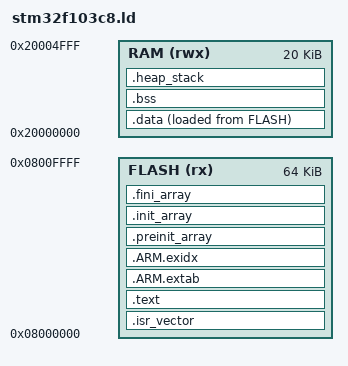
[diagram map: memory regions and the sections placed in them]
/* STM32F103C8: match the original Keil 64 KiB flash / 20 KiB RAM layout. */
ENTRY(Reset_Handler)

MEMORY
{
    FLASH (rx) : ORIGIN = 0x08000000, LENGTH = 64K
    RAM (rwx)  : ORIGIN = 0x20000000, LENGTH = 20K
}

_estack = ORIGIN(RAM) + LENGTH(RAM);
_Min_Heap_Size = 0x200;
_Min_Stack_Size = 0x400;

SECTIONS
{
    .isr_vector :
    {
        . = ALIGN(4);
        KEEP(*(.isr_vector))
    } > FLASH

    .text :
    {
        . = ALIGN(4);
        *(.text*)
        *(.rodata*)
        KEEP(*(.init))
        KEEP(*(.fini))
        . = ALIGN(4);
        _etext = .;
    } > FLASH

    .ARM.extab : { *(.ARM.extab* .gnu.linkonce.armextab.*) } > FLASH
    .ARM.exidx :
    {
        __exidx_start = .;
        *(.ARM.exidx*)
        __exidx_end = .;
    } > FLASH

    .preinit_array :
    {
        PROVIDE_HIDDEN(__preinit_array_start = .);
        KEEP(*(.preinit_array*))
        PROVIDE_HIDDEN(__preinit_array_end = .);
    } > FLASH
    .init_array :
    {
        PROVIDE_HIDDEN(__init_array_start = .);
        KEEP(*(SORT(.init_array.*)))
        KEEP(*(.init_array))
        PROVIDE_HIDDEN(__init_array_end = .);
    } > FLASH
    .fini_array :
    {
        PROVIDE_HIDDEN(__fini_array_start = .);
        KEEP(*(SORT(.fini_array.*)))
        KEEP(*(.fini_array))
        PROVIDE_HIDDEN(__fini_array_end = .);
    } > FLASH

    _sidata = LOADADDR(.data);
    .data :
    {
        . = ALIGN(4);
        _sdata = .;
        *(.data*)
        . = ALIGN(4);
        _edata = .;
    } > RAM AT > FLASH

    .bss (NOLOAD) :
    {
        . = ALIGN(4);
        _sbss = .;
        *(.bss*)
        *(COMMON)
        . = ALIGN(4);
        _ebss = .;
    } > RAM

    .heap_stack (NOLOAD) :
    {
        . = ALIGN(8);
        PROVIDE(end = .);
        PROVIDE(_end = .);
        . += _Min_Heap_Size;
        . += _Min_Stack_Size;
        . = ALIGN(8);
    } > RAM
    ASSERT(_ebss + _Min_Heap_Size + _Min_Stack_Size <= _estack,
           "RAM overflow: no room for heap and stack")
}
